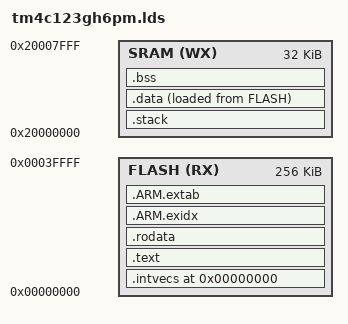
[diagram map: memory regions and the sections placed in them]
/******************************************************************************
 *
 * Default Linker script for the Texas Instruments TM4C123GH6PM
 *
 * This is derived from revision 15071 of the TivaWare Library.
 *
 *****************************************************************************/

MEMORY
{
    FLASH (RX) : ORIGIN = 0x00000000, LENGTH = 0x00040000
    SRAM (WX)  : ORIGIN = 0x20000000, LENGTH = 0x00008000
}
/* The size of the stack used by the application. NOTE: you need to adjust  */
STACK_SIZE = 512;


/* The size of the heap used by the application. NOTE: you need to adjust   */
HEAP_SIZE = 0;

/*
use the memory original name FLASH (ROM), and SRAM (RAM)
REGION_ALIAS("REGION_TEXT", FLASH);
REGION_ALIAS("REGION_BSS", SRAM);
REGION_ALIAS("REGION_DATA", SRAM);
REGION_ALIAS("REGION_STACK", SRAM);
REGION_ALIAS("REGION_HEAP", SRAM);
REGION_ALIAS("REGION_ARM_EXIDX", FLASH);
REGION_ALIAS("REGION_ARM_EXTAB", FLASH);
*/
SECTIONS {

    PROVIDE (_intvecs_base_address = 0x0);

    .intvecs (_intvecs_base_address) : AT (_intvecs_base_address) {
        KEEP (*(.intvecs))
    } > FLASH

/*
    PROVIDE (_vtable_base_address = 0x20000000);

    .vtable (_vtable_base_address) : AT (_vtable_base_address) {
        KEEP (*(.vtable))
    } > REGION_DATA
*/
    .text : {
        CREATE_OBJECT_SYMBOLS
        *(.text)
        *(.text.*)
        . = ALIGN(0x4);
        KEEP (*(.ctors))
        . = ALIGN(0x4);
        KEEP (*(.dtors))
        . = ALIGN(0x4);
        __init_array_start = .;
        KEEP (*(.init_array*))
        __init_array_end = .;
        *(.init)
        *(.fini*)
    } > FLASH

    PROVIDE (__etext = .);
    PROVIDE (_etext = .);
    PROVIDE (etext = .);

    .rodata : {
        *(.rodata)
        *(.rodata*)
    } > FLASH

/* make the satck at beginning of the RAM to avoid stack overflow from curapte other RAM sections
and make the core execute hard fault when stack overflow occurs*/
    .stack : {
        _stack = .;
        __stack = .;
        . = . + STACK_SIZE;
        . = ALIGN(4);
         __stack_end__ = .;
         __estack = .;
         _estack = .;
         estack = .;
    } > SRAM

    .data : ALIGN (4) {
        __data_load__ = LOADADDR (.data);
        __data_start__ = .;
        *(.data)
        *(.data*)
        . = ALIGN (4);
        __data_end__ = .;
    } > SRAM AT> FLASH

    .ARM.exidx : {
        __exidx_start = .;
        *(.ARM.exidx* .gnu.linkonce.armexidx.*)
        __exidx_end = .;
    } > FLASH

    .ARM.extab : {
        *(.ARM.extab* .gnu.linkonce.armextab.*)
    } > FLASH

    .bss : {
        __bss_start__ = .;
        *(.shbss)
        *(.bss)
        *(.bss.*)
        *(COMMON)
        . = ALIGN (4);
        __bss_end__ = .;
    } > SRAM

/*
delet the heap section
    .heap : {
        __heap_start__ = .;
        end = __heap_start__;
        _end = end;
        __end = end;
        KEEP(*(.heap))
        __heap_end__ = .;
        __HeapLimit = __heap_end__;
    } > REGION_HEAP
*/

/*
    .stack : ALIGN(0x8) {
        _stack = .;
        __stack = .;
        KEEP(*(.stack))
    } > REGION_STACK
*/
}
